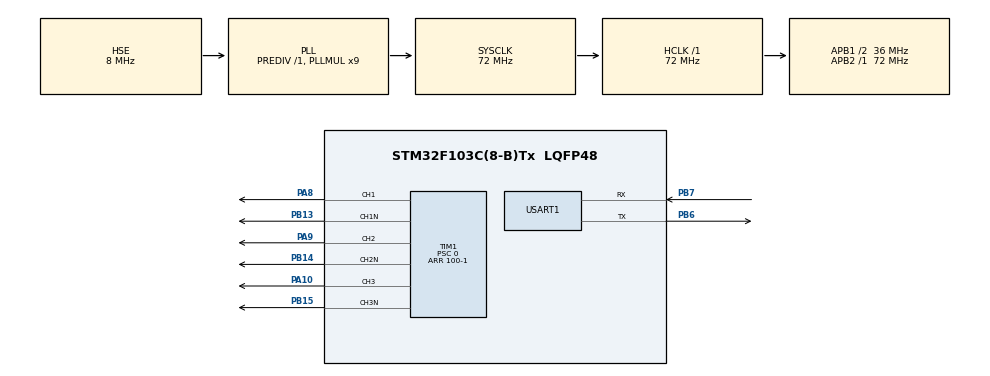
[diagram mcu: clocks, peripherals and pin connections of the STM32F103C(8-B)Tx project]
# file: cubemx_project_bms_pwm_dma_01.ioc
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Dma.Request0=TIM1_CH1
Dma.Request1=TIM1_CH2
Dma.Request2=TIM1_CH3
Dma.TIM1_CH1.0.Direction=DMA_MEMORY_TO_PERIPH
Dma.TIM1_CH1.0.Instance=DMA1_Channel2
Dma.TIM1_CH1.0.MemDataAlignment=DMA_MDATAALIGN_WORD
Dma.TIM1_CH1.0.MemInc=DMA_MINC_ENABLE
Dma.TIM1_CH1.0.Mode=DMA_NORMAL
Dma.TIM1_CH1.0.PeriphDataAlignment=DMA_PDATAALIGN_WORD
Dma.TIM1_CH1.0.PeriphInc=DMA_PINC_DISABLE
Dma.TIM1_CH1.0.Priority=DMA_PRIORITY_VERY_HIGH
Dma.TIM1_CH2.1.Direction=DMA_MEMORY_TO_PERIPH
Dma.TIM1_CH2.1.Instance=DMA1_Channel3
Dma.TIM1_CH2.1.MemDataAlignment=DMA_MDATAALIGN_WORD
Dma.TIM1_CH2.1.MemInc=DMA_MINC_ENABLE
Dma.TIM1_CH2.1.Mode=DMA_NORMAL
Dma.TIM1_CH2.1.PeriphDataAlignment=DMA_PDATAALIGN_WORD
Dma.TIM1_CH2.1.PeriphInc=DMA_PINC_DISABLE
Dma.TIM1_CH2.1.Priority=DMA_PRIORITY_VERY_HIGH
Dma.TIM1_CH3.2.Direction=DMA_MEMORY_TO_PERIPH
Dma.TIM1_CH3.2.Instance=DMA1_Channel6
Dma.TIM1_CH3.2.MemDataAlignment=DMA_MDATAALIGN_WORD
Dma.TIM1_CH3.2.MemInc=DMA_MINC_ENABLE
Dma.TIM1_CH3.2.Mode=DMA_NORMAL
Dma.TIM1_CH3.2.PeriphDataAlignment=DMA_PDATAALIGN_WORD
Dma.TIM1_CH3.2.PeriphInc=DMA_PINC_DISABLE
Dma.TIM1_CH3.2.Priority=DMA_PRIORITY_VERY_HIGH
Mcu.Family=STM32F1
Mcu.Name=STM32F103C(8-B)Tx
Mcu.Package=LQFP48
NVIC.DMA1_Channel2_IRQn=true\:3\:0\:true\:false\:true\:false\:true\:true
NVIC.DMA1_Channel3_IRQn=true\:3\:0\:true\:false\:true\:false\:true\:true
NVIC.DMA1_Channel6_IRQn=true\:3\:0\:true\:false\:true\:false\:true\:true
NVIC.PriorityGroup=NVIC_PRIORITYGROUP_4
NVIC.RCC_IRQn=true\:0\:0\:false\:false\:true\:true\:false\:true
NVIC.TIM1_CC_IRQn=true\:0\:0\:false\:false\:true\:true\:true\:true
NVIC.TIM1_UP_IRQn=true\:0\:0\:false\:false\:true\:true\:true\:true
NVIC.TIM2_IRQn=true\:0\:0\:true\:false\:true\:false\:true\:true
NVIC.TIM3_IRQn=true\:0\:0\:false\:false\:true\:true\:true\:true
NVIC.TimeBase=TIM2_IRQn
NVIC.TimeBaseIP=TIM2
NVIC.USART1_IRQn=true\:0\:0\:false\:false\:true\:true\:true\:true
PA10.GPIO_Speed=GPIO_SPEED_FREQ_HIGH
PA10.Signal=S_TIM1_CH3
PA13.Mode=Serial_Wire
PA13.Signal=SYS_JTMS-SWDIO
PA14.Mode=Serial_Wire
PA14.Signal=SYS_JTCK-SWCLK
PA8.GPIO_Speed=GPIO_SPEED_FREQ_HIGH
PA8.Signal=S_TIM1_CH1
PA9.GPIO_Speed=GPIO_SPEED_FREQ_HIGH
PA9.Signal=S_TIM1_CH2
PB13.GPIO_Speed=GPIO_SPEED_FREQ_HIGH
PB13.Mode=PWM Generation1 CH1 CH1N
PB13.Signal=TIM1_CH1N
PB14.GPIO_Speed=GPIO_SPEED_FREQ_HIGH
PB14.Mode=PWM Generation2 CH2 CH2N
PB14.Signal=TIM1_CH2N
PB15.GPIO_Speed=GPIO_SPEED_FREQ_HIGH
PB15.Mode=PWM Generation3 CH3 CH3N
PB15.Signal=TIM1_CH3N
PB6.Mode=Asynchronous
PB6.Signal=USART1_TX
PB7.Mode=Asynchronous
PB7.Signal=USART1_RX
PD0-OSC_IN.Mode=HSE-External-Oscillator
PD0-OSC_IN.Signal=RCC_OSC_IN
PD1-OSC_OUT.Mode=HSE-External-Oscillator
PD1-OSC_OUT.Signal=RCC_OSC_OUT
ProjectManager.HeapSize=0x200
ProjectManager.StackSize=0x400
ProjectManager.TargetToolchain=STM32CubeIDE
RCC.AHBFreq_Value=72000000
RCC.APB1CLKDivider=RCC_HCLK_DIV2
RCC.APB1Freq_Value=36000000
RCC.APB1TimFreq_Value=72000000
RCC.APB2Freq_Value=72000000
RCC.APB2TimFreq_Value=72000000
RCC.HCLKFreq_Value=72000000
RCC.PLLMUL=RCC_PLL_MUL9
RCC.PLLSourceVirtual=RCC_PLLSOURCE_HSE
RCC.SYSCLKFreq_VALUE=72000000
RCC.SYSCLKSource=RCC_SYSCLKSOURCE_PLLCLK
RCC.USBFreq_Value=72000000
SH.S_TIM1_CH1.0=TIM1_CH1,PWM Generation1 CH1 CH1N
SH.S_TIM1_CH2.0=TIM1_CH2,PWM Generation2 CH2 CH2N
SH.S_TIM1_CH3.0=TIM1_CH3,PWM Generation3 CH3 CH3N
TIM1.AutoReloadPreload=TIM_AUTORELOAD_PRELOAD_ENABLE
TIM1.Channel-PWM\ Generation1\ CH1\ CH1N=TIM_CHANNEL_1
TIM1.Channel-PWM\ Generation2\ CH2\ CH2N=TIM_CHANNEL_2
TIM1.Channel-PWM\ Generation3\ CH3\ CH3N=TIM_CHANNEL_3
TIM1.ClockDivision=TIM_CLOCKDIVISION_DIV2
TIM1.OC1Preload_PWM=DISABLE
TIM1.OC2Preload_PWM=DISABLE
TIM1.OC3Preload_PWM=DISABLE
TIM1.OCFastMode_PWM-PWM\ Generation1\ CH1\ CH1N=TIM_OCFAST_ENABLE
TIM1.OCFastMode_PWM-PWM\ Generation2\ CH2\ CH2N=TIM_OCFAST_ENABLE
TIM1.OCFastMode_PWM-PWM\ Generation3\ CH3\ CH3N=TIM_OCFAST_ENABLE
TIM1.Period=100-1
TIM1.Prescaler=0
TIM1.Pulse-PWM\ Generation1\ CH1\ CH1N=0
TIM1.Pulse-PWM\ Generation2\ CH2\ CH2N=0
TIM1.Pulse-PWM\ Generation3\ CH3\ CH3N=0
TIM1.TIM_MasterOutputTrigger=TIM_TRGO_RESET
TIM1.TIM_MasterSlaveMode=TIM_MASTERSLAVEMODE_DISABLE
TIM3.Period=1000-1
TIM3.Prescaler=72-1
USART1.VirtualMode=VM_ASYNC
VP_SYS_VS_tim2.Mode=TIM2
VP_TIM1_VS_ClockSourceINT.Mode=Internal
VP_TIM3_VS_ClockSourceINT.Mode=Internal
board=custom

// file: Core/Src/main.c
/* USER CODE BEGIN Header */
/**
  ******************************************************************************
  * @file           : main.c
  * @brief          : Main program body
  ******************************************************************************
  * @attention
  *
  * Copyright (c) 2024 STMicroelectronics.
  * All rights reserved.
  *
  * This software is licensed under terms that can be found in the LICENSE file
  * in the root directory of this software component.
  * If no LICENSE file comes with this software, it is provided AS-IS.
  *
  ******************************************************************************
  */
/* USER CODE END Header */
#include "main.h"

TIM_HandleTypeDef htim1;
TIM_HandleTypeDef htim3;
DMA_HandleTypeDef hdma_tim1_ch1;
DMA_HandleTypeDef hdma_tim1_ch2;
DMA_HandleTypeDef hdma_tim1_ch3;

UART_HandleTypeDef huart1;

/* USER CODE BEGIN PV */
uint16_t pwmData1[] = {30};
uint16_t pwmData2[] = {40};
uint16_t pwmData3[] = {50};

/* USER CODE END PV */

void SystemClock_Config(void);
static void MX_GPIO_Init(void);
static void MX_DMA_Init(void);
static void MX_TIM1_Init(void);
static void MX_USART1_UART_Init(void);
static void MX_TIM3_Init(void);

int main(void)
{

  /* MCU Configuration--------------------------------------------------------*/

  /* Reset of all peripherals, Initializes the Flash interface and the Systick. */
  HAL_Init();

  /* Configure the system clock */
  SystemClock_Config();

  /* Initialize all configured peripherals */
  MX_GPIO_Init();
  MX_DMA_Init();
  MX_TIM1_Init();
  MX_USART1_UART_Init();
  MX_TIM3_Init();
  /* USER CODE BEGIN 2 */
  HAL_TIM_PWM_Start_DMA(&htim1, TIM_CHANNEL_1, (uint32_t*)pwmData1, sizeof(pwmData1));
  HAL_TIM_PWM_Start_DMA(&htim1, TIM_CHANNEL_2, (uint32_t*)pwmData2, sizeof(pwmData2));
  HAL_TIM_PWM_Start_DMA(&htim1, TIM_CHANNEL_3, (uint32_t*)pwmData3, sizeof(pwmData3));

  HAL_TIMEx_PWMN_Start_DMA(&htim1, TIM_CHANNEL_1, (uint32_t*)pwmData1, sizeof(pwmData1));
  HAL_TIMEx_PWMN_Start_DMA(&htim1, TIM_CHANNEL_2, (uint32_t*)pwmData2, sizeof(pwmData2));
  HAL_TIMEx_PWMN_Start_DMA(&htim1, TIM_CHANNEL_3, (uint32_t*)pwmData3, sizeof(pwmData3));

  /* USER CODE END 2 */

  /* Infinite loop */
  while (1)
  {

  }
}

void SystemClock_Config(void)
{
  RCC_OscInitTypeDef RCC_OscInitStruct = {0};
  RCC_ClkInitTypeDef RCC_ClkInitStruct = {0};

  /** Initializes the RCC Oscillators according to the specified parameters
  * in the RCC_OscInitTypeDef structure.
  */
  RCC_OscInitStruct.OscillatorType = RCC_OSCILLATORTYPE_HSE;
  RCC_OscInitStruct.HSEState = RCC_HSE_ON;
  RCC_OscInitStruct.HSEPredivValue = RCC_HSE_PREDIV_DIV1;
  RCC_OscInitStruct.HSIState = RCC_HSI_ON;
  RCC_OscInitStruct.PLL.PLLState = RCC_PLL_ON;
  RCC_OscInitStruct.PLL.PLLSource = RCC_PLLSOURCE_HSE;
  RCC_OscInitStruct.PLL.PLLMUL = RCC_PLL_MUL9;
  if (HAL_RCC_OscConfig(&RCC_OscInitStruct) != HAL_OK)
  {
    Error_Handler();
  }

  /** Initializes the CPU, AHB and APB buses clocks
  */
  RCC_ClkInitStruct.ClockType = RCC_CLOCKTYPE_HCLK|RCC_CLOCKTYPE_SYSCLK
                              |RCC_CLOCKTYPE_PCLK1|RCC_CLOCKTYPE_PCLK2;
  RCC_ClkInitStruct.SYSCLKSource = RCC_SYSCLKSOURCE_PLLCLK;
  RCC_ClkInitStruct.AHBCLKDivider = RCC_SYSCLK_DIV1;
  RCC_ClkInitStruct.APB1CLKDivider = RCC_HCLK_DIV2;
  RCC_ClkInitStruct.APB2CLKDivider = RCC_HCLK_DIV1;

  if (HAL_RCC_ClockConfig(&RCC_ClkInitStruct, FLASH_LATENCY_2) != HAL_OK)
  {
    Error_Handler();
  }
}

static void MX_TIM1_Init(void)
{

  TIM_ClockConfigTypeDef sClockSourceConfig = {0};
  TIM_MasterConfigTypeDef sMasterConfig = {0};
  TIM_OC_InitTypeDef sConfigOC = {0};
  TIM_BreakDeadTimeConfigTypeDef sBreakDeadTimeConfig = {0};

  htim1.Instance = TIM1;
  htim1.Init.Prescaler = 0;
  htim1.Init.CounterMode = TIM_COUNTERMODE_UP;
  htim1.Init.Period = 100-1;
  htim1.Init.ClockDivision = TIM_CLOCKDIVISION_DIV2;
  htim1.Init.RepetitionCounter = 0;
  htim1.Init.AutoReloadPreload = TIM_AUTORELOAD_PRELOAD_ENABLE;
  if (HAL_TIM_Base_Init(&htim1) != HAL_OK)
  {
    Error_Handler();
  }
  sClockSourceConfig.ClockSource = TIM_CLOCKSOURCE_INTERNAL;
  if (HAL_TIM_ConfigClockSource(&htim1, &sClockSourceConfig) != HAL_OK)
  {
    Error_Handler();
  }
  if (HAL_TIM_PWM_Init(&htim1) != HAL_OK)
  {
    Error_Handler();
  }
  sMasterConfig.MasterOutputTrigger = TIM_TRGO_RESET;
  sMasterConfig.MasterSlaveMode = TIM_MASTERSLAVEMODE_DISABLE;
  if (HAL_TIMEx_MasterConfigSynchronization(&htim1, &sMasterConfig) != HAL_OK)
  {
    Error_Handler();
  }
  sConfigOC.OCMode = TIM_OCMODE_PWM1;
  sConfigOC.Pulse = 0;
  sConfigOC.OCPolarity = TIM_OCPOLARITY_HIGH;
  sConfigOC.OCNPolarity = TIM_OCNPOLARITY_HIGH;
  sConfigOC.OCFastMode = TIM_OCFAST_ENABLE;
  sConfigOC.OCIdleState = TIM_OCIDLESTATE_RESET;
  sConfigOC.OCNIdleState = TIM_OCNIDLESTATE_RESET;
  if (HAL_TIM_PWM_ConfigChannel(&htim1, &sConfigOC, TIM_CHANNEL_1) != HAL_OK)
  {
    Error_Handler();
  }
  __HAL_TIM_DISABLE_OCxPRELOAD(&htim1, TIM_CHANNEL_1);
  if (HAL_TIM_PWM_ConfigChannel(&htim1, &sConfigOC, TIM_CHANNEL_2) != HAL_OK)
  {
    Error_Handler();
  }
  __HAL_TIM_DISABLE_OCxPRELOAD(&htim1, TIM_CHANNEL_2);
  if (HAL_TIM_PWM_ConfigChannel(&htim1, &sConfigOC, TIM_CHANNEL_3) != HAL_OK)
  {
    Error_Handler();
  }
  __HAL_TIM_DISABLE_OCxPRELOAD(&htim1, TIM_CHANNEL_3);
  sBreakDeadTimeConfig.OffStateRunMode = TIM_OSSR_DISABLE;
  sBreakDeadTimeConfig.OffStateIDLEMode = TIM_OSSI_DISABLE;
  sBreakDeadTimeConfig.LockLevel = TIM_LOCKLEVEL_OFF;
  sBreakDeadTimeConfig.DeadTime = 0;
  sBreakDeadTimeConfig.BreakState = TIM_BREAK_DISABLE;
  sBreakDeadTimeConfig.BreakPolarity = TIM_BREAKPOLARITY_HIGH;
  sBreakDeadTimeConfig.AutomaticOutput = TIM_AUTOMATICOUTPUT_DISABLE;
  if (HAL_TIMEx_ConfigBreakDeadTime(&htim1, &sBreakDeadTimeConfig) != HAL_OK)
  {
    Error_Handler();
  }
  HAL_TIM_MspPostInit(&htim1);

}

static void MX_TIM3_Init(void)
{

  TIM_ClockConfigTypeDef sClockSourceConfig = {0};
  TIM_MasterConfigTypeDef sMasterConfig = {0};

  htim3.Instance = TIM3;
  htim3.Init.Prescaler = 72-1;
  htim3.Init.CounterMode = TIM_COUNTERMODE_UP;
  htim3.Init.Period = 1000-1;
  htim3.Init.ClockDivision = TIM_CLOCKDIVISION_DIV1;
  htim3.Init.AutoReloadPreload = TIM_AUTORELOAD_PRELOAD_DISABLE;
  if (HAL_TIM_Base_Init(&htim3) != HAL_OK)
  {
    Error_Handler();
  }
  sClockSourceConfig.ClockSource = TIM_CLOCKSOURCE_INTERNAL;
  if (HAL_TIM_ConfigClockSource(&htim3, &sClockSourceConfig) != HAL_OK)
  {
    Error_Handler();
  }
  sMasterConfig.MasterOutputTrigger = TIM_TRGO_RESET;
  sMasterConfig.MasterSlaveMode = TIM_MASTERSLAVEMODE_DISABLE;
  if (HAL_TIMEx_MasterConfigSynchronization(&htim3, &sMasterConfig) != HAL_OK)
  {
    Error_Handler();
  }

}

static void MX_USART1_UART_Init(void)
{

  huart1.Instance = USART1;
  huart1.Init.BaudRate = 115200;
  huart1.Init.WordLength = UART_WORDLENGTH_8B;
  huart1.Init.StopBits = UART_STOPBITS_1;
  huart1.Init.Parity = UART_PARITY_NONE;
  huart1.Init.Mode = UART_MODE_TX_RX;
  huart1.Init.HwFlowCtl = UART_HWCONTROL_NONE;
  huart1.Init.OverSampling = UART_OVERSAMPLING_16;
  if (HAL_UART_Init(&huart1) != HAL_OK)
  {
    Error_Handler();
  }

}

static void MX_DMA_Init(void)
{

  /* DMA controller clock enable */
  __HAL_RCC_DMA1_CLK_ENABLE();

  /* DMA interrupt init */
  /* DMA1_Channel2_IRQn interrupt configuration */
  HAL_NVIC_SetPriority(DMA1_Channel2_IRQn, 3, 0);
  HAL_NVIC_EnableIRQ(DMA1_Channel2_IRQn);
  /* DMA1_Channel3_IRQn interrupt configuration */
  HAL_NVIC_SetPriority(DMA1_Channel3_IRQn, 3, 0);
  HAL_NVIC_EnableIRQ(DMA1_Channel3_IRQn);
  /* DMA1_Channel6_IRQn interrupt configuration */
  HAL_NVIC_SetPriority(DMA1_Channel6_IRQn, 3, 0);
  HAL_NVIC_EnableIRQ(DMA1_Channel6_IRQn);

}

static void MX_GPIO_Init(void)
{

  /* GPIO Ports Clock Enable */
  __HAL_RCC_GPIOD_CLK_ENABLE();
  __HAL_RCC_GPIOB_CLK_ENABLE();
  __HAL_RCC_GPIOA_CLK_ENABLE();

}

/* USER CODE BEGIN 4 */
void HAL_TIM_PWM_PulseFinishedCallback(TIM_HandleTypeDef *htim)
{
	HAL_TIM_PWM_Stop_DMA(&htim1, TIM_CHANNEL_1);
//	HAL_TIM_PWM_Stop_DMA(&htim1, TIM_CHANNEL_2);
//	HAL_TIM_PWM_Stop_DMA(&htim1, TIM_CHANNEL_3);
}
/* USER CODE END 4 */

void HAL_TIM_PeriodElapsedCallback(TIM_HandleTypeDef *htim)
{
  if (htim->Instance == TIM2) {
    HAL_IncTick();
  }
}

void Error_Handler(void)
{
  __disable_irq();
  while (1)
  {
  }
}
